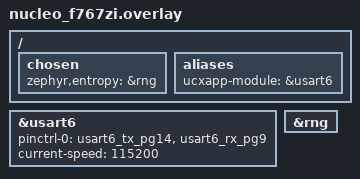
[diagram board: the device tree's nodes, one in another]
/* NORA-W36 on the Arduino header CN10 (same wiring as the FreeRTOS build):
 * module TX -> D0 = PG9 (USART6_RX), module RX <- D1 = PG14 (USART6_TX).
 * The shell stays on the ST-Link virtual COM port (USART3, zephyr,console). */

/ {
	chosen {
		/* Hardware TRNG: the only entropy source of the HTTPS web UI (ucxapp_rng_zephyr.c). */
		zephyr,entropy = &rng;
	};

	aliases {
		ucxapp-module = &usart6;
	};
};

&usart6 {
	pinctrl-0 = <&usart6_tx_pg14 &usart6_rx_pg9>;
	pinctrl-names = "default";
	current-speed = <115200>;
	status = "okay";
};

&rng {
	status = "okay";
};
